# DA1469x register map
Vendor: Dialog; Series: DA1469x; File version: 1.2
CPU: CM33 r1p0, little endian, no MPU, FPU, 3 interrupt priority bits
Registers are 32-bit, read-write, reset 0x0 unless marked. A register's access mark holds for its fields unless they carry their own. Offsets are from the block's base; [hi:lo] are bit positions; {n}, {i} and the like mark numbered series; 'fields as' and 'values as' point back to an identical list.

## DMA — DMA registers
Base 0x50040800
{0x0+0x20*i} DMA{i}_A_START_REG (reset mask 0x7FFFFFFF) (i=0..6) — Start address A of DMA channel {i}
  [31:0] DMA{i}_A_START — Source start address
{0x4+0x20*i} DMA{i}_B_START_REG (reset mask 0x7FFFFFFF) (i=0..6) — Start address B of DMA channel {i}
  [31:0] DMA{i}_B_START — Destination start address
{0x8+0x20*i} DMA{i}_INT_REG (i=0..7) — DMA receive interrupt register channel {i}
  [15:0] DMA{i}_INT — Number of transfers until an interrupt is generated. The interrupt is generated after a transfer, if DMAx_INT_REG is equal to DMAx_IDX_REG and before DMAx_IDX_REG is incremented. The bit-field IRQ_ENABLE of DMAx_CTRL_REG must be set to '1' to let the controller generate the interrupt.
{0xC+0x20*i} DMA{i}_LEN_REG (i=0..7) — DMA receive length register channel {i}
  [15:0] DMA{i}_LEN — DMA channel's transfer length. DMAx_LEN of value 0, 1, 2, ... results into an actual transfer length of 1, 2, 3, ...
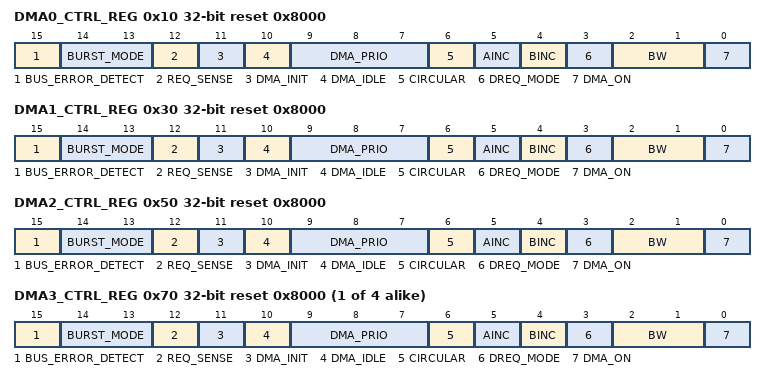
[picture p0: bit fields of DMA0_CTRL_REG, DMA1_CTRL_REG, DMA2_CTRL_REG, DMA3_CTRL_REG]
0x10 DMA0_CTRL_REG reset 0x8000 — Control register for the DMA channel 0
  [15] BUS_ERROR_DETECT — 0 = Ignores bus error response from the AHB bus, so DMA continues normally. 1 = Detects the bus response and tracks any bus error may occur during the transfer. If a bus error is detected, the channel completes the current read-write DMA cycle (either in burst or single transfers mode) and then closes the transfer, de-asserting DMA_ON bit automatically. It is noted that the respective bus error detection status bit of DMA_INT_STATUS_REG is automatically cleared as soon as the channel is switched-on again, in order to perform a new transfer.
  [14:13] BURST_MODE — Enables the DMA read/write bursts, according to the following configuration: 00 = Bursts are disabled 01 = Bursts of 4 are enabled 10 = Bursts of 8 are enabled 11 = Reserved
  [12] REQ_SENSE — 0 = DMA operates with level-sensitive peripheral requests (default) 1 = DMA operates with (positive) edge-sensitive peripheral requests
  [11] DMA_INIT — 0 = DMA performs copy A1 to B1, A2 to B2, etc ... 1 = DMA performs copy of A1 to B1, B2, etc ... This feature is useful for memory initialization to any value. Thus, BINC must be set to '1', while AINC is don't care, as only one fetch from A is done. This process cannot be interrupted by other DMA channels. It is also noted that DMA_INIT should not be used when DREQ_MODE='1'.
  [10] DMA_IDLE — 0 = Blocking mode, the DMA performs a fast back-to-back copy, disabling bus access for any bus master with lower priority. 1 = Interrupting mode, the DMA inserts a wait cycle after each store allowing the CPU to steal cycles or cache to perform a burst read. If DREQ_MODE='1', DMA_IDLE is don't care.
  [9:7] DMA_PRIO — The priority level determines which DMA channel will be granted access for transferring data, in case more than one channels are active and request the bus at the same time. The greater the value, the higher the priority. In specific: 000 = lowest priority 111 = highest priority If different channels with equal priority level values request the bus at the same time, an inherent priority mechanism is applied. According to this mechanism, if, for example, both the DMA0 and DMA1 channels have the same priority level, then DMA0 will first be granted access to the bus.
  [6] CIRCULAR — 0 = Normal mode. The DMA channel stops after having completed the transfer of length determined by DMAx_LEN_REG. DMA_ON automatically deasserts when the transfer is completed. 1 = Circular mode (applicable only if DREQ_MODE = '1'). In this mode, DMA_ON never deasserts, as the DMA channel automatically resets DMAx_IDX_REG and starts a new transfer.
  [5] AINC — Enable increment of source address. 0 = do not increment (source address stays the same during the transfer) 1 = increment according to the value of BW bit-field (by 1, when BW="00" ; by 2, when BW="01" ; by 4, when BW="10")
  [4] BINC — Enable increment of destination address. 0 = do not increment (destination address stays the same during the transfer) 1 = increment according to the value of BW bit-field (by 1, when BW="00" ; by 2, when BW="01" ; by 4, when BW="10")
  [3] DREQ_MODE — 0 = DMA channel starts immediately 1 = DMA channel must be triggered by peripheral DMA request (see also the description of DMA_REQ_MUX_REG)
  [2:1] BW — Bus transfer width: 00 = 1 Byte (suggested for peripherals like UART and 8-bit SPI) 01 = 2 Bytes (suggested for peripherals like I2C and 16-bit SPI) 10 = 4 Bytes (suggested for Memory-to-Memory transfers) 11 = Reserved
  [0] DMA_ON — 0 = DMA channel is off, clocks are disabled 1 = DMA channel is enabled. This bit will be automatically cleared after the completion of a transfer, if circular mode is not enabled. In circular mode, this bit stays set. Note: If DMA_ON is disabled by SW while the DMA channel is active, it cannot be enabled again until the channel has completed the last on-going read-write cycle and has stopped. Thus, the SW has to check that the reading of DMAx_CTRL_REG.DMA_ON returns 0, before setting again the specific bit-field.
{0x14+0x20*i} DMA{i}_IDX_REG (i=0..7) — Index value of DMA channel {i}
  [15:0] DMA{i}_IDX ro — This (read-only) register determines the data items already transferred by the DMA channel. Hence, if its value is 1, then the DMA channel has already copied one data item and it is currently performing the next copy. If its value is 2, then two items have already been copied and so on. When the transfer is completed (so when DMAx_CTRL_REG.DMA_ON has been cleared) and DMAx_CTRL_REG.CIRCULAR is not set, the register keeps its (last) value (which should be equal to DMAx_LEN_REG) and it is automatically reset to 0 upon starting a new transfer. In CIRCULAR mode, the register is automatically initialized to 0 as soon as the DMA channel starts-over again.
0x30 DMA1_CTRL_REG reset 0x8000 — Control register for the DMA channel 1
  fields as DMA0_CTRL_REG
0x50 DMA2_CTRL_REG reset 0x8000 — Control register for the DMA channel 2
  [15] BUS_ERROR_DETECT — 0 = Ignores bus error response from the AHB bus, so DMA continues normally. 1 = Detects the bus response and tracks any bus error may occur during the transfer. If a bus error is detected, the channel completes the current read-write DMA cycle (either in burst or single transfers mode) and then closes the transfer, de-asserting DMA_ON bit automatically. It is noted that the respective bus error detection status bit of DMA_INT_STATUS_REG is automatically cleared as soon as the channel is switched-on again, in order to perform a new transfer.
  [14:13] BURST_MODE — Enables the DMA read/write bursts, according to the following configuration: 00 = Bursts are disabled 01 = Bursts of 4 are enabled 10 = Bursts of 8 are enabled 11 = Reserved
  [12] REQ_SENSE — 0 = DMA operates with level-sensitive peripheral requests (default) 1 = DMA operates with (positive) edge-sensitive peripheral requests
  [11] DMA_INIT — 0 = DMA performs copy A1 to B1, A2 to B2, etc ... 1 = DMA performs copy of A1 to B1, B2, etc ... This feature is useful for memory initialization to any value. Thus, BINC must be set to '1', while AINC is don't care, as only one fetch from A is done. This process cannot be interrupted by other DMA channels. It is also noted that DMA_INIT should not be used when DREQ_MODE='1'.
  [10] DMA_IDLE — 0 = Blocking mode, the DMA performs a fast back-to-back copy, disabling bus access for any bus master with lower priority. 1 = Interrupting mode, the DMA inserts a wait cycle after each store allowing the CPU to steal cycles or cache to perform a burst read. If DREQ_MODE='1', DMA_IDLE is don't care.
  [9:7] DMA_PRIO — The priority level determines which DMA channel will be granted access for transferring data, in case more than one channels are active and request the bus at the same time. The greater the value, the higher the priority. In specific: 000 = lowest priority 111 = highest priority If different channels with equal priority level values request the bus at the same time, an inherent priority mechanism is applied. According to this mechanism, if, for example, both the DMA0 and DMA1 channels have the same priority level, then DMA0 will first be granted access to the bus.
  [6] CIRCULAR — 0 = Normal mode. The DMA channel stops after having completed the transfer of length determined by DMAx_LEN_REG. DMA_ON automatically deasserts when the transfer is completed. 1 = Circular mode (applicable only if DREQ_MODE = '1'). In this mode, DMA_ON never deasserts, as the DMA channel automatically resets DMAx_IDX_REG and starts a new transfer.
  [5] AINC — Enable increment of destination address. 0 = do not increment (destination address stays the same during the transfer) 1 = increment according to the value of BW bit-field (by 1, when BW="00" ; by 2, when BW="01" ; by 4, when BW="10")
  [4] BINC — Enable increment of destination address 0 = do not increment 1 = increment according value of BW
  [3] DREQ_MODE — 0 = DMA channel starts immediately 1 = DMA channel must be triggered by peripheral DMA request (see also the description of DMA_REQ_MUX_REG)
  [2:1] BW — Bus transfer width: 00 = 1 Byte (suggested for peripherals like UART and 8-bit SPI) 01 = 2 Bytes (suggested for peripherals like I2C and 16-bit SPI) 10 = 4 Bytes (suggested for Memory-to-Memory transfers) 11 = Reserved
  [0] DMA_ON — 0 = DMA channel is off, clocks are disabled 1 = DMA channel is enabled. This bit will be automatically cleared after the completion of a transfer, if circular mode is not enabled. In circular mode, this bit stays set. Note: If DMA_ON is disabled by SW while the DMA channel is active, it cannot be enabled again until the channel has completed the last on-going read-write cycle and has stopped. Thus, the SW has to check that the reading of DMAx_CTRL_REG.DMA_ON returns 0, before setting again the specific bit-field.
{0x10+0x20*i} DMA{i}_CTRL_REG reset 0x8000 (i=3..6) — Control register for the DMA channel {i}
  fields as DMA0_CTRL_REG
0xE0 DMA7_A_START_REG (reset mask 0x7FFFFFFF) — Start address A of DMA channel 7
  [31:0] DMA7_A_START — Source start address NOTE: See also the DMA chapter of the Datasheet for the allowed range of the DMA7 channel's source address in Secure Boot mode.
0xE4 DMA7_B_START_REG (reset mask 0x7FFFFFFF) — Start address B of DMA channel 7
  [31:0] DMA7_B_START — Destination start address NOTE: See also the DMA chapter of the Datasheet for the allowed range of the DMA7 channel's destination address in Secure Boot mode.
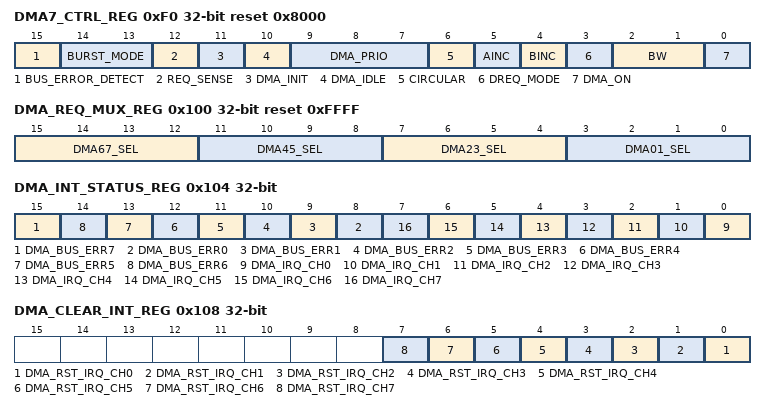
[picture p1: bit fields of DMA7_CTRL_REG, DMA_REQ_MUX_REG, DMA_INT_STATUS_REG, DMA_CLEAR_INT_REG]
0xF0 DMA7_CTRL_REG reset 0x8000 — Control register for the DMA channel 7
  [15] BUS_ERROR_DETECT — 0 = Ignores bus error response from the AHB bus, so DMA continues normally. 1 = Detects the bus response and tracks any bus error may occur during the transfer. If a bus error is detected, the channel completes the current read-write DMA cycle (either in burst or single transfers mode) and then closes the transfer, de-asserting DMA_ON bit automatically. It is noted that the respective bus error detection status bit of DMA_INT_STATUS_REG is automatically cleared as soon as the channel is switched-on again, in order to perform a new transfer. NOTE: In secure boot mode, the bus error detection mode of DMA7 channel is always enabled, overruling the specific bit-field's programmed value.
  [14:13] BURST_MODE — Enables the DMA read/write bursts, according to the following configuration: 00 = Bursts are disabled 01 = Bursts of 4 are enabled 10 = Bursts of 8 are enabled 11 = Reserved
  [12] REQ_SENSE — 0 = DMA operates with level-sensitive peripheral requests (default) 1 = DMA operates with (positive) edge-sensitive peripheral requests
  [11] DMA_INIT — 0 = DMA performs copy A1 to B1, A2 to B2, etc ... 1 = DMA performs copy of A1 to B1, B2, etc ... This feature is useful for memory initialization to any value. Thus, BINC must be set to '1', while AINC is don't care, as only one fetch from A is done. This process cannot be interrupted by other DMA channels. It is also noted that DMA_INIT should not be used when DREQ_MODE='1'. NOTE: This bit-field is overruled to '0' when the DMA7 channel is configured as "trusted" channel (in Secure Boot mode).
  [10] DMA_IDLE — 0 = Blocking mode, the DMA performs a fast back-to-back copy, disabling bus access for any bus master with lower priority. 1 = Interrupting mode, the DMA inserts a wait cycle after each store allowing the CPU to steal cycles or cache to perform a burst read. If DREQ_MODE='1', DMA_IDLE is don't care. *NOTE: This bit-field is overruled to '0' when the DMA7 channel is configured as "trusted" channel (in Secure Boot mode).
  [9:7] DMA_PRIO — The priority level determines which DMA channel will be granted access for transferring data, in case more than one channels are active and request the bus at the same time. The greater the value, the higher the priority. In specific: 000 = lowest priority 111 = highest priority If different channels with equal priority level values request the bus at the same time, an inherent priority mechanism is applied. According to this mechanism, if, for example, both the DMA0 and DMA1 channels have the same priority level, then DMA0 will first be granted access to the bus.
  [6] CIRCULAR — 0 = Normal mode. The DMA channel stops after having completed the transfer of length determined by DMAx_LEN_REG. DMA_ON automatically deasserts when the transfer is completed. 1 = Circular mode (applicable only if DREQ_MODE = '1'). In this mode, DMA_ON never deasserts, as the DMA channel automatically resets DMAx_IDX_REG and starts a new transfer.
  [5] AINC — Enable increment of source address. 0 = do not increment (source address stays the same during the transfer) 1 = increment according to the value of BW bit-field (by 1, when BW="00" ; by 2, when BW="01" ; by 4, when BW="10")
  [4] BINC — Enable increment of destination address. 0 = do not increment (destination address stays the same during the transfer) 1 = increment according to the value of BW bit-field (by 1, when BW="00" ; by 2, when BW="01" ; by 4, when BW="10")
  [3] DREQ_MODE — 0 = DMA channel starts immediately 1 = DMA channel must be triggered by peripheral DMA request (see also the description of DMA_REQ_MUX_REG) *NOTE: This bit-field is overruled to '0' when channel DMA7 is configured as "trusted" channel (in Secure Boot mode).
  [2:1] BW — Bus transfer width: 00 = 1 Byte (suggested for peripherals like UART and 8-bit SPI) 01 = 2 Bytes (suggested for peripherals like I2C and 16-bit SPI) 10 = 4 Bytes (suggested for Memory-to-Memory transfers) 11 = Reserved NOTE: This bit-field is overruled to "10" when channel DMA7 is configured as "trusted" channel (in Secure Boot mode).
  [0] DMA_ON — 0 = DMA channel is off, clocks are disabled 1 = DMA channel is enabled. This bit will be automatically cleared after the completion of a transfer, if circular mode is not enabled. In circular mode, this bit stays set. Note: If DMA_ON is disabled by SW while the DMA channel is active, it cannot be enabled again until the channel has completed the last on-going read-write cycle and has stopped. Thus, the SW has to check that the reading of DMAx_CTRL_REG.DMA_ON returns 0, before setting again the specific bit-field.
0x100 DMA_REQ_MUX_REG reset 0xFFFF — DMA channel assignments
  [15:12] DMA67_SEL — Select which combination of peripherals are mapped on the DMA channels. The peripherals are mapped as pairs on two channels. Here, the first DMA request is mapped on channel 6 and the second on channel 7. See DMA01_SEL for the peripheral mapping.
  [11:8] DMA45_SEL — Select which combination of peripherals are mapped on the DMA channels. The peripherals are mapped as pairs on two channels. Here, the first DMA request is mapped on channel 4 and the second on channel 5. See DMA01_SEL for the peripherals' mapping.
  [7:4] DMA23_SEL — Select which combination of peripherals are mapped on the DMA channels. The peripherals are mapped as pairs on two channels. Here, the first DMA request is mapped on channel 2 and the second on channel 3. See DMA01_SEL for the peripherals' mapping.
  [3:0] DMA01_SEL — Select which combination of peripherals are mapped on the DMA channels. The peripherals are mapped as pairs on two channels. Here, the first DMA request is mapped on channel 0 and the second on channel 1. 0x0: SPI_rx / SPI_tx 0x1: SPI2_rx / SPI2_tx 0x2: UART_rx / UART_tx 0x3: UART2_rx / UART2_tx 0x4: I2C_rx / I2C_tx 0x5: I2C2_rx / I2C2_tx 0x6: USB_rx / USB_tx 0x7: UART3_rx/UART3_tx 0x8: PCM_rx / PCM_tx 0x9: SRC_out / SRC_in (for all the supported conversions) 0xA: Reserved 0xB: Reserved 0xC: GP_ADC / - 0xD: SD_ADC / - 0xE: Reserved 0xF: None Note: If any of the four available peripheral selector fields (DMA01_SEL, DMA23_SEL, DMA45_SEL, DMA67_SEL) have the same value, the lesser significant selector has higher priority and will control the DMA acknowledge signal driven to the selected peripheral. Hence, if DMA01_SEL = DMA23_SEL, the channels 0 and 1 will provide the Rx and Tx DMA acknowledge signals for the selected peripheral. Consequently, it is suggested to assign the intended peripheral value to a unique selector field.
0x104 DMA_INT_STATUS_REG — DMA interrupt status register
  [15] DMA_BUS_ERR7 ro — 0 = No bus error response is detected for channel 7 1 = Bus error response detected for channel 7 NOTE: This bit-field is auto-clear and it is initialized to '0' as soon as a new transfer is started.It is also noted that when the specific channel becomes secure (so when either of the PROT_AES_KEY_READ and PROT_QSPI_KEY_READ bits of SECURE_BOOT_REG is set), this bit-field is overruled to '0', masking the bus error status reporting to the user.
  [n+8] DMA_BUS_ERR{n} ro (n=0..6) — 0 = No bus error response is detected for channel {n} 1 = Bus error response detected for channel {n} NOTE: This bit-field is auto-clear and it is initialized to '0' as soon as a new transfer is started.
  [n] DMA_IRQ_CH{n} ro (n=0..7) — 0 = IRQ on channel {n} is not set 1 = IRQ on channel {n} is set
0x108 DMA_CLEAR_INT_REG — DMA clear interrupt register
  [n] DMA_RST_IRQ_CH{n} wo (n=0..7) — Writing a 1 will reset the status bit of DMA_INT_STATUS_REG for channel {n} ; writing a 0 will have no effect
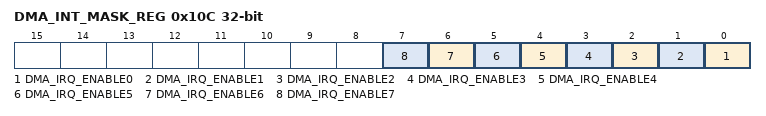
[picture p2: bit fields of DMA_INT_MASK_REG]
0x10C DMA_INT_MASK_REG — DMA Interrupt mask register
  [n] DMA_IRQ_ENABLE{n} (n=0..7) — 0 = disable interrupts on channel {n} 1 = enable interrupts on channel {n}
